# clcd_reva_me10 register map
Registers are access not given, no defined reset value unless marked. A register's access mark holds for its fields unless they carry their own. Offsets are from the block's base; lines under a group give offsets from that group; [hi:lo] are bit positions; {n}, {i} and the like mark numbered series; 'fields as' and 'values as' point back to an identical list; <NAME> marks a mode.

## Memory map
0x40031000 CLCD size 0xFFF — Color LCD Controller

## CLCD — Color LCD Controller
Base 0x40031000
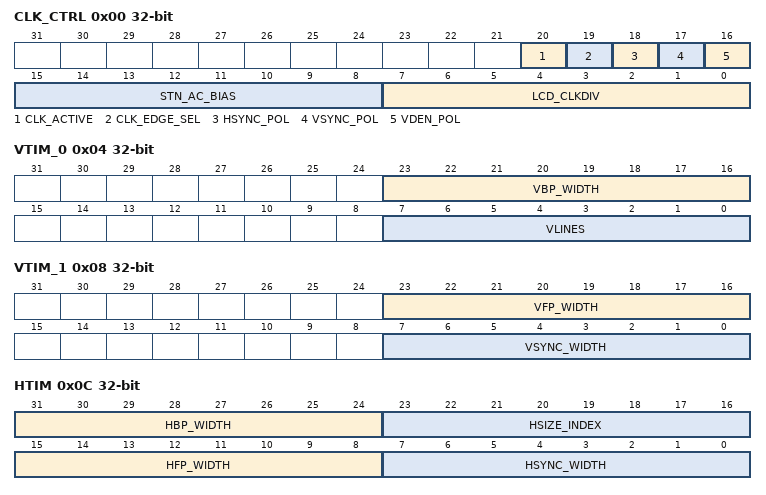
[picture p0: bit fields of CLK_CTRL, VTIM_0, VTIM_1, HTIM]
0x00 CLK_CTRL — LCD Clock Control Register
  [20] CLK_ACTIVE — Clock Active on Data. If the display type is Color STN 8-bit, this bit selects if the CLCD_CLK output is active always or only during data output to the display.
    0=ALWAYS (Always Active); 1=ONDATA (ACTIVE ON DATA)
  [19] CLK_EDGE_SEL — Clock Edge Selection. This field controls the clock edge that is used by the LCD panel to sample the data and signal lines.
    0=RISING (Rising edge); 1=FALLING (Falling Edge)
  [18] HSYNC_POL — HSYNC Polarity Selection. This field sets the polarity of the horizontal sync signal output pin.
    0=ACTIVELO (Active Low); 1=ACTIVEHI
  [17] VSYNC_POL — VSYNC Polarity Selection. This field sets the polarity of the vertical sync signal output pin.
    0=ACTIVELO (Active Low); 1=ACTIVEHI
  [16] VDEN_POL — CLCD_VDEN Polarity Selection. This field sets the polarity of the video enable signal output pin.
    0=ACTIVELO (Active Low); 1=ACTIVEHI (Active High)
  [15:8] STN_AC_BIAS — AC Bias Frequency Control. This field sets the AC Bias Frequency output on the CLCD_VDEN pin for Color StN display mode.
  [7:0] LCD_CLKDIV — Clock divsor
0x04 VTIM_0 — LCD Vertical Timing 0 Register
  [23:16] VBP_WIDTH — V BACK PORCH
  [7:0] VLINES
0x08 VTIM_1 — LCD Vertical Timing 1 Register
  [23:16] VFP_WIDTH — V Front PORCH
  [7:0] VSYNC_WIDTH
0x0C HTIM — LCD Horizontal Timing Register.
  [31:24] HBP_WIDTH — Horizontal Back Porch size in CLCD Clocks from 1 to 256 -> HBP= (HBACKPORCH+1)
  [23:16] HSIZE_INDEX — Horizontal Front Porch Size in Pixels = (HSIZE + 1) *16
  [15:8] HFP_WIDTH — Horizontal Front Porch size in lines from 1 to 256
  [7:0] HSYNC_WIDTH — Horizontal Sync Width in CLCD Clocks from 1 to 256 HSync Width = HSYNCWIDTH+1 Clocks
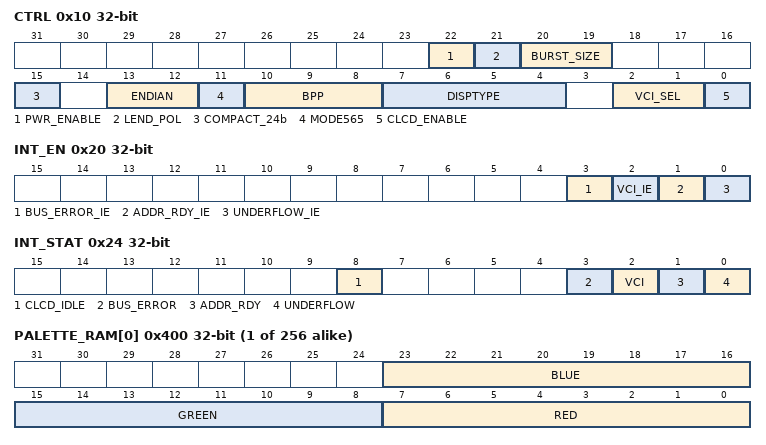
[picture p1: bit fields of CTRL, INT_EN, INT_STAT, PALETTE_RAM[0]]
0x10 CTRL — LCD Control Register
  [22] PWR_ENABLE — Display Power Enable. Enables power to the display using the PWREN output pin.
    0=LO (Power enable pin is set low.); 1=HI (Power enable pin is set high.)
  [21] LEND_POL — LEND Polarity Selection. This field sets the polarity of the line end signal output pin.
    0=ACTIVELO (Active Low); 1=ACTIVEHI (Active High)
  [20:19] BURST_SIZE — BURST
    0=4WORDS (4 32-bit words.); 1=8WORDS (8 32-bit words.); 2=16WORDS (16 32-bit words.)
  [15] COMPACT_24b — C24
    0=1_PFR (1 pixel per frame buffer entry); 1=1ANDA3RD_PFR (1 and 1/3 pixels per fram buffer entry)
  [13:12] ENDIAN — EMODE
    0=LBLP (LLBP); 1=BBBP; 2=LBBP
  [11] MODE565
    0=BGR556 (MODE 556); 1=RGB565 (MODE 565)
  [10:8] BPP
    0=BPP1; 1=BPP2; 2=BPP4; 3=BPP8; 4=BPP16; 5=BPP24
  [7:4] DISPTYPE — Display Type
    4=8BITCOLORSTN (STN Color 8 bit); 8=TFT
  [2:1] VCI_SEL — Vertical Compare Interrupt Source Select
    0=ON_VSYNC (On Vertical Sync); 1=ON_VBP (On Vertical Back Porch); 2=ON_VDEN (On Active Video); 3=ON_VFP (On Vertical Front Porch)
  [0] CLCD_ENABLE — LCD Enable
    0=dis (Disable); 1=en (Enable)
0x18 FRBUF — Frame buffer.
  [31:0] FRAME_ADDR — Set this field to the beginning of the fram buffer data to display.
0x20 INT_EN — LCD Interrupt Enable Register.
  [all] fields
    0=dis (Interrupt disabled.); 1=en (Interrupt enabled.)
  [3] BUS_ERROR_IE — BERR Interrupt Enable
  [2] VCI_IE — VCI Interrupt Enable
  [1] ADDR_RDY_IE — Address Ready Interrupt Enable
  [0] UNDERFLOW_IE — Underflow Interrupt Enable
0x24 INT_STAT write-1-clears — LCD Status Register.
  [8] CLCD_IDLE — LCD IDLE Staus
    0=IDLE; 1=BUSY
  [3] BUS_ERROR — BERR Interrupt Status
    on read: 0=inactive (No interrupt pending); 1=pend (Interrupt pending) | on write: 1=Clears the interrupt flag
  [2] VCI — VCI Interrupt Status
    values as BUS_ERROR
  [1] ADDR_RDY — Address Ready Interrupt Status
    values as BUS_ERROR
  [0] UNDERFLOW — Underflow Interrupt Status
    values as BUS_ERROR
{0x400+4i} PALETTE_RAM[{i}] (i=0..255) — Palette
  [23:16] BLUE — Blue Data for Pallet Entry.
  [15:8] GREEN — Green Data for Pallet Entry.
  [7:0] RED — Red Data for Pallet Entry.
